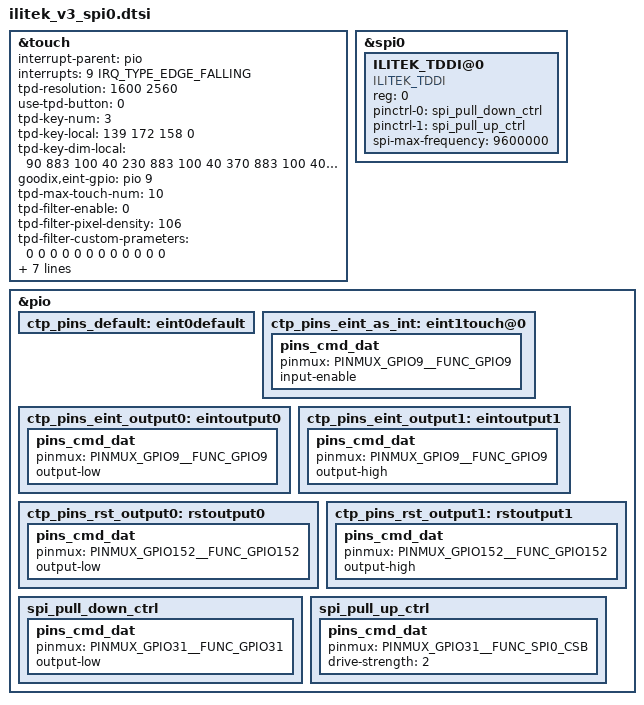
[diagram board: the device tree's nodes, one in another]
// SPDX-License-Identifier: GPL-2.0+
/*
 * Copyright (c) 2019 MediaTek Inc.
 *
 */

/* TOUCH start */
&touch {
	interrupt-parent = <&pio>;
	interrupts = <9 IRQ_TYPE_EDGE_FALLING>;
	tpd-resolution = <1600 2560>;
	use-tpd-button = <0>;
	tpd-key-num = <3>;
	tpd-key-local= <139 172 158 0>;
	tpd-key-dim-local = <90 883 100 40 230
				 883 100 40 370 883 100 40 0 0 0 0>;
	goodix,eint-gpio = <&pio 9 0x0>;
	tpd-max-touch-num = <10>;
	tpd-filter-enable = <0>;
	tpd-filter-pixel-density = <106>;
	tpd-filter-custom-prameters = <0 0 0 0 0 0 0 0 0 0 0 0>;
	tpd-filter-custom-speed = <0 0 0>;
	pinctrl-names = "default", "state_eint_as_int", "state_eint_output0",
		"state_eint_output1", "state_rst_output0", "state_rst_output1";
	pinctrl-0 = <&ctp_pins_default>;
	pinctrl-1 = <&ctp_pins_eint_as_int>;
	pinctrl-2 = <&ctp_pins_eint_output0>;
	pinctrl-3 = <&ctp_pins_eint_output1>;
	pinctrl-4 = <&ctp_pins_rst_output0>;
	pinctrl-5 = <&ctp_pins_rst_output1>;
	status = "okay";
};

&spi0 {
	status = "okay";
	#address-cells = <1>;
	#size-cells = <0>;
	ILITEK_TDDI@0 {
		compatible = "ILITEK_TDDI";
		reg = <0>; //Same as CS ID
		status = "okay";
		pinctrl-names = "spi_pull_down", "spi_pull_up";
		pinctrl-0 = <&spi_pull_down_ctrl>;
		pinctrl-1 = <&spi_pull_up_ctrl>;
		spi-max-frequency = <9600000>;
	};
};

&pio {
	ctp_pins_default: eint0default {
	};
	ctp_pins_eint_as_int: eint1touch@0 {
		pins_cmd_dat {
			pinmux = <PINMUX_GPIO9__FUNC_GPIO9>;
			input-enable;
		};
	};
	ctp_pins_eint_output0: eintoutput0 {
		pins_cmd_dat {
			pinmux = <PINMUX_GPIO9__FUNC_GPIO9>;
			output-low;
		};
	};
	ctp_pins_eint_output1: eintoutput1 {
		pins_cmd_dat {
			pinmux = <PINMUX_GPIO9__FUNC_GPIO9>;
			output-high;
		};
	};
	ctp_pins_rst_output0: rstoutput0 {
		pins_cmd_dat {
			pinmux = <PINMUX_GPIO152__FUNC_GPIO152>;
			output-low;
		};
	};
	ctp_pins_rst_output1: rstoutput1 {
		pins_cmd_dat {
			pinmux = <PINMUX_GPIO152__FUNC_GPIO152>;
			output-high;
		};
	};


	spi_pull_down_ctrl: spi_pull_down_ctrl {
		pins_cmd_dat {
			pinmux = <PINMUX_GPIO31__FUNC_GPIO31>;
			output-low;
		};
	};
	
	spi_pull_up_ctrl: spi_pull_up_ctrl {
		pins_cmd_dat {
			pinmux = <PINMUX_GPIO31__FUNC_SPI0_CSB>;
			drive-strength = <2>;
		};
	};
};
